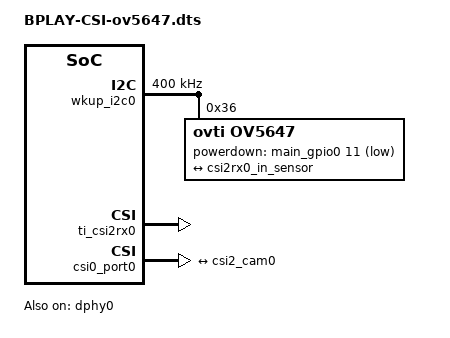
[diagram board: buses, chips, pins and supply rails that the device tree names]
// SPDX-License-Identifier: GPL-2.0
/*
 * Copyright (C) 2022 Texas Instruments Incorporated - https://www.ti.com/
 */

/dts-v1/;
/plugin/;

#include <dt-bindings/gpio/gpio.h>

/*
 * Helper to show loaded overlays under: /proc/device-tree/chosen/overlays/
 */
&{/chosen} {
	overlays {
		PLAY-CSI-ov5647.kernel = __TIMESTAMP__;
	};
};

/ {
	fragment@101 {
		target-path = "/";

		__overlay__ {
			clk_ov5647_fixed: ov5647-xclk {
				compatible = "fixed-clock";
				#clock-cells = <0>;
				clock-frequency = <12000000>;
			};
		};
	};
};

&wkup_i2c0 {
	status = "okay";
	/* Pick conservative frequency to match up with as many modules */
	clock-frequency = <400000>;

	ov5647: camera@36 {
		compatible = "ovti,ov5647";
		reg = <0x36>;

		clocks = <&clk_ov5647_fixed>;
		clock-names = "xclk";
		/* rPI csi2 modules hook reset and power signals together */
		powerdown-gpios = <&main_gpio0 11 GPIO_ACTIVE_LOW>;

		port {
			csi2_cam0: endpoint {
				remote-endpoint = <&csi2rx0_in_sensor>;
				clock-lanes = <0>;
				data-lanes = <1 2>;
			};
		};
	};
};

&dphy0 {
	status = "okay";
};

&ti_csi2rx0 {
	status = "okay";
};

&csi0_port0 {
	status = "okay";

	csi2rx0_in_sensor: endpoint {
		remote-endpoint = <&csi2_cam0>;
		bus-type = <4>; /* CSI2 DPHY. */
		clock-lanes = <0>;
		data-lanes = <1 2>;
	};
};
